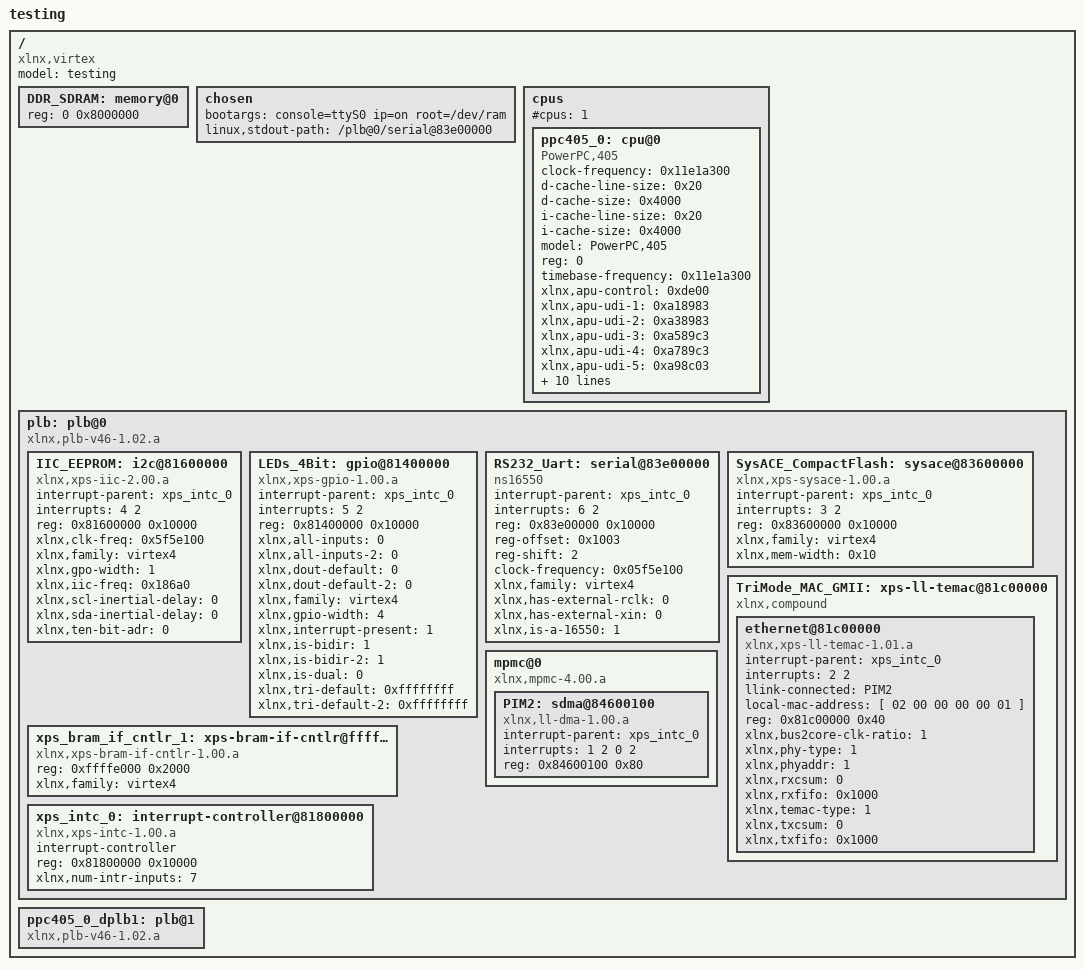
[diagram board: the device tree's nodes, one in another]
/*
 * This file supports the Xilinx ML405 board with the 405 processor.
 * A reference design for the FPGA is provided at http://git.xilinx.com.
 *
 * (C) Copyright 2008 Xilinx, Inc.
 *
 * This file is licensed under the terms of the GNU General Public License
 * version 2. This program is licensed "as is" without any warranty of any
 * kind, whether express or implied.
 */

/dts-v1/;

/ {
	#address-cells = <1>;
	#size-cells = <1>;
	compatible = "xlnx,virtex";
	model = "testing";
	DDR_SDRAM: memory@0 {
		device_type = "memory";
		reg = < 0 0x8000000 >;
	} ;
	chosen {
		bootargs = "console=ttyS0 ip=on root=/dev/ram";
		linux,stdout-path = "/plb@0/serial@83e00000";
	} ;
	cpus {
		#address-cells = <1>;
		#cpus = <1>;

		#size-cells = <0>;
		ppc405_0: cpu@0 {
			clock-frequency = <0x11e1a300>;
			compatible = "PowerPC,405", "ibm,ppc405";
			d-cache-line-size = <0x20>;
			d-cache-size = <0x4000>;
			device_type = "cpu";
			i-cache-line-size = <0x20>;
			i-cache-size = <0x4000>;
			model = "PowerPC,405";
			reg = <0>;
			timebase-frequency = <0x11e1a300>;
			xlnx,apu-control = <0xde00>;
			xlnx,apu-udi-1 = <0xa18983>;
			xlnx,apu-udi-2 = <0xa38983>;
			xlnx,apu-udi-3 = <0xa589c3>;
			xlnx,apu-udi-4 = <0xa789c3>;
			xlnx,apu-udi-5 = <0xa98c03>;
			xlnx,apu-udi-6 = <0xab8c03>;
			xlnx,apu-udi-7 = <0xad8c43>;
			xlnx,apu-udi-8 = <0xaf8c43>;
			xlnx,deterministic-mult = <0>;
			xlnx,disable-operand-forwarding = <1>;
			xlnx,fastest-plb-clock = "DPLB0";
			xlnx,generate-plb-timespecs = <1>;
			xlnx,mmu-enable = <1>;
			xlnx,pvr-high = <0>;
			xlnx,pvr-low = <0>;
		} ;
	} ;
	plb: plb@0 {
		#address-cells = <1>;
		#size-cells = <1>;
		compatible = "xlnx,plb-v46-1.02.a", "simple-bus";
		ranges ;
		IIC_EEPROM: i2c@81600000 {
			compatible = "xlnx,xps-iic-2.00.a";
			interrupt-parent = <&xps_intc_0>;
			interrupts = < 4 2 >;
			reg = < 0x81600000 0x10000 >;
			xlnx,clk-freq = <0x5f5e100>;
			xlnx,family = "virtex4";
			xlnx,gpo-width = <1>;
			xlnx,iic-freq = <0x186a0>;
			xlnx,scl-inertial-delay = <0>;
			xlnx,sda-inertial-delay = <0>;
			xlnx,ten-bit-adr = <0>;
		} ;
		LEDs_4Bit: gpio@81400000 {
			compatible = "xlnx,xps-gpio-1.00.a";
			interrupt-parent = <&xps_intc_0>;
			interrupts = < 5 2 >;
			reg = < 0x81400000 0x10000 >;
			xlnx,all-inputs = <0>;
			xlnx,all-inputs-2 = <0>;
			xlnx,dout-default = <0>;
			xlnx,dout-default-2 = <0>;
			xlnx,family = "virtex4";
			xlnx,gpio-width = <4>;
			xlnx,interrupt-present = <1>;
			xlnx,is-bidir = <1>;
			xlnx,is-bidir-2 = <1>;
			xlnx,is-dual = <0>;
			xlnx,tri-default = <0xffffffff>;
			xlnx,tri-default-2 = <0xffffffff>;
		} ;
		RS232_Uart: serial@83e00000 {
			compatible = "ns16550";
			device_type = "serial";
			interrupt-parent = <&xps_intc_0>;
			interrupts = < 6 2 >;
			reg = < 0x83e00000 0x10000 >;
			reg-offset = <0x1003>;
			reg-shift = <2>; 
			clock-frequency = <0x05f5e100>;
			xlnx,family = "virtex4";
			xlnx,has-external-rclk = <0>;
			xlnx,has-external-xin = <0>;
			xlnx,is-a-16550 = <1>;
		} ;
		SysACE_CompactFlash: sysace@83600000 {
			compatible = "xlnx,xps-sysace-1.00.a";
			interrupt-parent = <&xps_intc_0>;
			interrupts = < 3 2 >;
			reg = < 0x83600000 0x10000 >;
			xlnx,family = "virtex4";
			xlnx,mem-width = <0x10>;
		} ;
		TriMode_MAC_GMII: xps-ll-temac@81c00000 {
			#address-cells = <1>;
			#size-cells = <1>;
			compatible = "xlnx,compound";
			ethernet@81c00000 {
				compatible = "xlnx,xps-ll-temac-1.01.a";
				device_type = "network";
				interrupt-parent = <&xps_intc_0>;
				interrupts = < 2 2 >;
				llink-connected = <&PIM2>;
				local-mac-address = [ 02 00 00 00 00 01 ];
				reg = < 0x81c00000 0x40 >;
				xlnx,bus2core-clk-ratio = <1>;
				xlnx,phy-type = <1>;
				xlnx,phyaddr = <1>;
				xlnx,rxcsum = <0>;
				xlnx,rxfifo = <0x1000>;
				xlnx,temac-type = <1>;
				xlnx,txcsum = <0>;
				xlnx,txfifo = <0x1000>;
			} ;
		} ;
		mpmc@0 {
			#address-cells = <1>;
			#size-cells = <1>;
			compatible = "xlnx,mpmc-4.00.a";
			PIM2: sdma@84600100 {
				compatible = "xlnx,ll-dma-1.00.a";
				interrupt-parent = <&xps_intc_0>;
				interrupts = < 1 2 0 2 >;
				reg = < 0x84600100 0x80 >;
			} ;
		} ;
		xps_bram_if_cntlr_1: xps-bram-if-cntlr@ffffe000 {
			compatible = "xlnx,xps-bram-if-cntlr-1.00.a";
			reg = < 0xffffe000 0x2000 >;
			xlnx,family = "virtex4";
		} ;
		xps_intc_0: interrupt-controller@81800000 {
			#interrupt-cells = <2>;
			compatible = "xlnx,xps-intc-1.00.a";
			interrupt-controller ;
			reg = < 0x81800000 0x10000 >;
			xlnx,num-intr-inputs = <7>;
		} ;
	} ;
	ppc405_0_dplb1: plb@1 {
		#address-cells = <1>;
		#size-cells = <1>;
		compatible = "xlnx,plb-v46-1.02.a", "simple-bus";
		ranges ;
	} ;
}  ;
